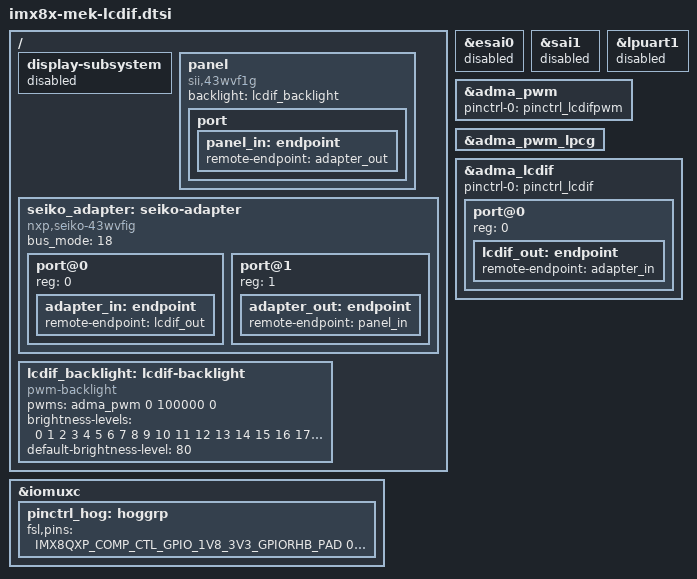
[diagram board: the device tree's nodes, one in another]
// SPDX-License-Identifier: GPL-2.0
/*
 * Copyright 2020 NXP.
 */

/ {
	display-subsystem {
		status = "disabled";
	};

	panel {
		compatible = "sii,43wvf1g";
		backlight = <&lcdif_backlight>;

		port {
			panel_in: endpoint {
				remote-endpoint = <&adapter_out>;
			};
		};
	};

	seiko_adapter: seiko-adapter {
		#address-cells = <1>;
		#size-cells = <0>;
		compatible = "nxp,seiko-43wvfig";
		bus_mode = <18>;

		port@0 {
			reg = <0>;
			adapter_in: endpoint {
				remote-endpoint = <&lcdif_out>;
			};
		};
		port@1 {
			reg = <1>;
			adapter_out: endpoint {
				remote-endpoint = <&panel_in>;
			};
		};
	};

	lcdif_backlight: lcdif-backlight {
		compatible = "pwm-backlight";
		pwms = <&adma_pwm 0 100000 0>;
		status = "okay";

		brightness-levels = < 0  1  2  3  4  5  6  7  8  9
				     10 11 12 13 14 15 16 17 18 19
				     20 21 22 23 24 25 26 27 28 29
				     30 31 32 33 34 35 36 37 38 39
				     40 41 42 43 44 45 46 47 48 49
				     50 51 52 53 54 55 56 57 58 59
				     60 61 62 63 64 65 66 67 68 69
				     70 71 72 73 74 75 76 77 78 79
				     80 81 82 83 84 85 86 87 88 89
				     90 91 92 93 94 95 96 97 98 99
				    100>;
		default-brightness-level = <80>;
	};
};

&iomuxc {
	/delete-node/ pinctrl_hog;

	pinctrl_hog: hoggrp {
		fsl,pins = <
			IMX8QXP_COMP_CTL_GPIO_1V8_3V3_GPIORHB_PAD  0x000514a0
		>;
	};
};

&esai0 {
	status = "disabled";
};

&sai1 {
	status = "disabled";
};

&lpuart1 {
	status = "disabled";
};

&adma_pwm {
	pinctrl-names = "default";
	pinctrl-0 = <&pinctrl_lcdifpwm>;
	status = "okay";
};

&adma_pwm_lpcg {
	status = "okay";
};


&adma_lcdif {
	pinctrl-names = "default";
	pinctrl-0 = <&pinctrl_lcdif>;
	status = "okay";

	#address-cells = <1>;
	#size-cells = <0>;

	port@0 {
		reg = <0>;
		lcdif_out: endpoint {
			remote-endpoint = <&adapter_in>;
		};
	};
};
